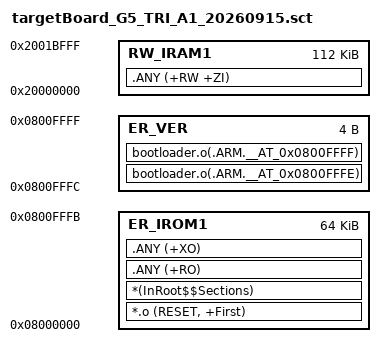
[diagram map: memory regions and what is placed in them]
; *************************************************************
; *** Scatter-Loading Description File - custom for bootloader ***
; *************************************************************

LR_IROM1 0x08000000 0x0000FFFC  {
  ER_IROM1 0x08000000 0x0000FFFC  {
   *.o (RESET, +First)
   *(InRoot$$Sections)
   .ANY (+RO)
   .ANY (+XO)
  }
  RW_IRAM1 0x20000000 0x0001C000  {
   .ANY (+RW +ZI)
  }
}
LR_VER 0x0800FFFC 0x00000004  {
  ER_VER 0x0800FFFC 0x00000004  {
   bootloader.o(.ARM.__AT_0x0800FFFE)
   bootloader.o(.ARM.__AT_0x0800FFFF)
  }
}
